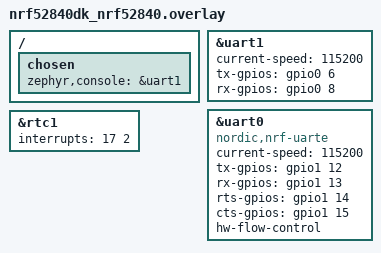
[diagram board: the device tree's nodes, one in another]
/* SPDX-License-Identifier: Apache-2.0 */

/ {
	chosen {
		zephyr,console = &uart1;
	};
};

&uart1 {
	current-speed = <115200>;
	status = "okay";
	tx-gpios = <&gpio0 6 0>;
	rx-gpios = <&gpio0 8 0>;
};

&uart0 {
	compatible = "nordic,nrf-uarte";
	current-speed = <115200>;
	status = "okay";
	tx-gpios = <&gpio1 12 0>;
	rx-gpios = <&gpio1 13 0>;
	rts-gpios = <&gpio1 14 0>;
	cts-gpios = <&gpio1 15 0>;
	hw-flow-control;
};

&rtc1 {
	interrupts = <17 2>;
};
